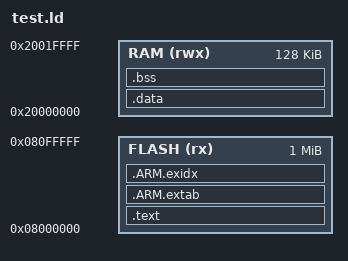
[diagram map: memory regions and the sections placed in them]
/* 软件模拟专用链接脚本，正式固件通过 EIDE/Keil 链接。 */
ENTRY(test_run)
MEMORY {
    FLASH (rx) : ORIGIN = 0x08000000, LENGTH = 1024K
    RAM (rwx) : ORIGIN = 0x20000000, LENGTH = 128K
}
SECTIONS {
    .text : { *(.text*) *(.rodata*) } > FLASH
    .ARM.extab : { *(.ARM.extab*) } > FLASH
    .ARM.exidx : { *(.ARM.exidx*) } > FLASH
    .data : { *(.data*) } > RAM
    .bss : { *(.bss*) *(COMMON) } > RAM
    end = .;
    _end = .;
}
